# IDMA register map
Vendor: Texas Instruments
Peripheral module from a debugger description file (folder omap34xx).
Registers are 32-bit, read-write, reset values left out (the file's numbers can be read two ways) unless marked. A register's access mark holds for its fields unless they carry their own. Offsets are as the file gives them; lines under a group give offsets from that group; [hi:lo] are bit positions; {n}, {i} and the like mark numbered series; 'fields as' and 'values as' point back to an identical list; <NAME> marks a mode.

## IDMA
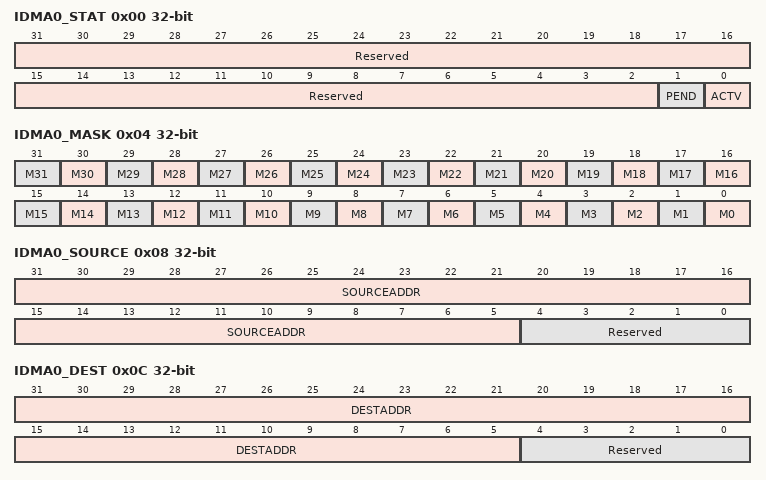
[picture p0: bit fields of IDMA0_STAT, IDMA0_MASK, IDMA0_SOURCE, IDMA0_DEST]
0x00 IDMA0_STAT ro — IDMA Channel 0 Status Register
  [31:2] Reserved — Reads return 0s
  [1] PEND — Pending transfer: Set when control registers are written to by the CPU and there is already an active transfer in progress (ACTV = 1) and cleared when the transfer becomes active.PEND = 1: Transfer is pending PEND = 0: No pending transfer
  [0] ACTV — Active transfer: Set when channel 0 begins reading data from the source address and cleared following the last write to the destination address.ACTV = 1: Active transfer ACTV = 0: No active transfer
0x04 IDMA0_MASK — IDMA Channel 0 Mask Register
  [n] M{n} (n=0..31) — Register Mask bit:M{n} = 1: Register access blocked (masked)M{n} = 0: Register access permitted (not masked)
0x08 IDMA0_SOURCE — IDMA Channel 0 Source Address Register
  [31:5] SOURCEADDR — Source Address: Must point to a 32-byte-aligned (e.g. window-aligned) memory location local to DSP megamodule or to a valid configuration register space.
  [4:0] Reserved — Write 0s for future compatibility.Read returns 0.
0x0C IDMA0_DEST — IDMA Channel 0 Destination Address Register
  [31:5] DESTADDR — Destination Address: Must point to a 32-byte-aligned (e.g. windowaligned) memory location local to DSP megamodule or to a valid configuration register space.
  [4:0] Reserved — Write 0s for future compatibility.Read returns 0.
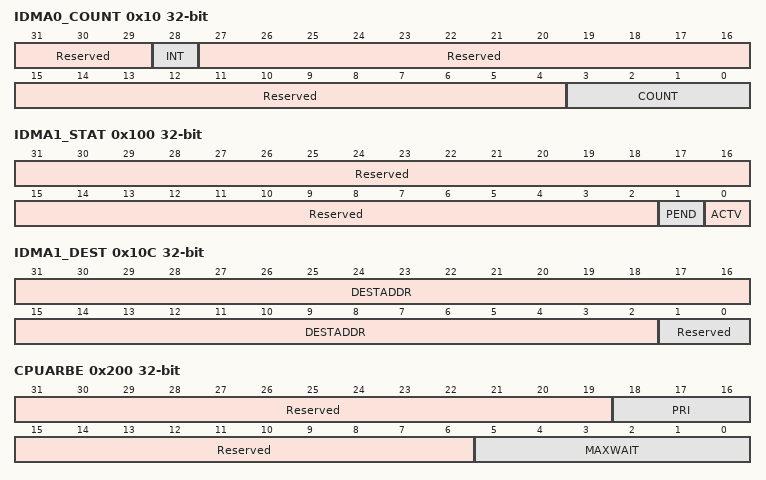
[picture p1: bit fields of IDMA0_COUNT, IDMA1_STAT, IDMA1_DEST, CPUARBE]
0x10 IDMA0_COUNT — IDMA Channel 0 Count Register
  [31:29] Reserved — Write 0s for future compatibility. Read returns 0.
  [28] INT — CPU interrupt enable INT = 1: Interrupt CPU (IDMA_INT0) on completion INT = 0: Do not interrupt CPU on completion
  [27:4] Reserved — Write 0s for future compatibility. Read returns 0.
  [3:0] COUNT — Window count COUNT = 0000: Transfer to/from one 32-word window COUNT = n: Transfer to/from n+1 32-word windows
0x100 IDMA1_STAT ro — IDMA Channel 1 Status Register
  [31:2] Reserved — Write 0s for future compatibility.Read returns 0.
  [1] PEND — Pending transfer: Set when control registers are written to by the CPU and there is already an active transfer in progress (ACTV = 1) and cleared when the transfer becomes active.PEND = 1: Transfer is pendingPEND = 0: No pending transfer
  [0] ACTV — Active transfer: Set when channel 1 begins reading data from the source address and cleared following the last write to the destination address.ACTV = 1: Active transferACTV = 0: No active transfer
0x108 IDMA1_SOURCE — IDMA Channel 1 Source Address Register
  [31:0] SOURCEADDR — Source Address: Must point to a word-aligned memory location local to GEM. When performing a block fill (IDMA1_COUNT.FILL = 1) the source address is the fill value. Note that when performing a Fill Mode transfer all 32-bits of the SOURCEADDR are writeable and when performing a linear transfer the two LSBs are implemented as 00b.
0x10C IDMA1_DEST access per field — IDMA Channel 1 Destination Address Register
  [31:2] DESTADDR rw — Destination Address: Must point to a word-aligned memory location local to DSP megamodule.
  [1:0] Reserved ro — Reads return 0sWrite 0 for further compaibility
0x200 CPUARBE — CPU Arbitration Control
  [31:19] Reserved — Write 0s for future compatibility.Read returns 0.
  [18:16] PRI — Priority
    0=Highest priority; 1=2nd highest priority; 2=3rd highest priority; {v}={v+1}th highest priority (v=3..6); 7=Lowest priority
  [15:6] Reserved — Write 0s for future compatibility.Read returns 0.
  [5:0] MAXWAIT — Maximum Wait time (in UMC/EMC cycles)
    0=Always stalls due to higher priority requestor; 1=Maximum wait of 1 cycles (1/2 = 50% access); 2=Maximum wait of 2 cycles (1/3 = 33% access); 4=Maximum wait of 4 cycles (1/5 = 20% access); 8=Maximum wait of 8 cycles (1/9 = 11% access); 16=Maximum wait of 16 cycles (1/17 = 6% access); 32=Maximum wait of 32 cycles (1/33 = 3% access)
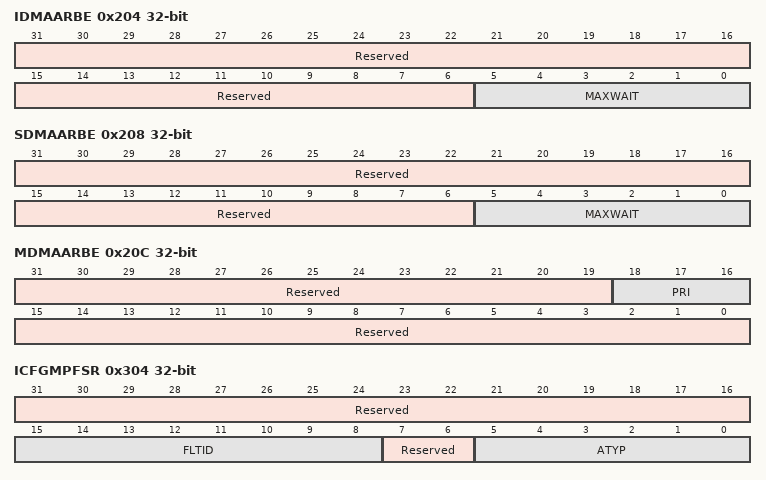
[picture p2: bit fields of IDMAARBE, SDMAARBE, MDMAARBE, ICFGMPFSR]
0x204 IDMAARBE — IDMA Arbitration control
  [31:6] Reserved — Write 0s for future compatibility.Read returns 0.
  [5:0] MAXWAIT — Maximum Wait time (in UMC/EMC cycles)
    values as CPUARBE.MAXWAIT
0x208 SDMAARBE
  fields as IDMAARBE
0x20C MDMAARBE
  [31:19] Reserved — Write 0s for future compatibility.Read returns 0.
  [18:16] PRI — Priority
    values as CPUARBE.PRI
  [15:0] Reserved — Write 0s for future compatibility.Read returns 0.
0x300 ICFGMPFAR ro — ICFG Memory Protection Fault Address Register
  [31:0] ADDR — Fault Address
0x304 ICFGMPFSR ro — ICFG Memory Protection Fault Status Register
  [31:16] Reserved — Write 0s for future compatibility.Read returns 0.
  [15:8] FLTID — Faulted ID:VBUS PrivID of faulting requestor. This field is valid only if LE is zero.
  [7:6] Reserved — Write 0s for future compatibility.Read returns 0.
  [5:0] ATYP — Access type
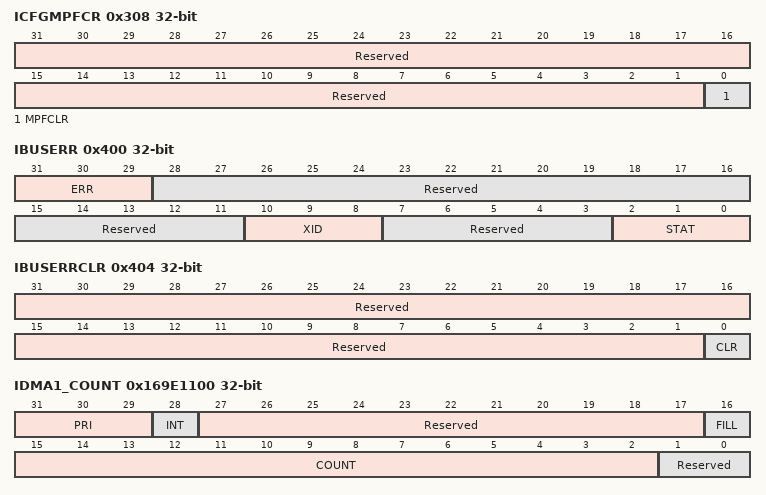
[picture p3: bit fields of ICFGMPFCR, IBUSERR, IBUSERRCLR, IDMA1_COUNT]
0x308 ICFGMPFCR wo — ICFG Memory Protection Fault Command Register
  [31:1] Reserved — Write 0s for future compatibility.Read returns 0.
  [0] MPFCLR — Write 0: No effectWrite 1: Clear fault logged information
0x400 IBUSERR ro — Bus Access Error Register
  [31:29] ERR — Error detected
    0=No error; 1=MDMA Read Status Error detected; 2=MDMA Write Status Error detected; 3=CFG Read Status Error detected; 4=CFG Write Status Error detected
  [28:11] Reserved — Write 0s for future compatibility.Read returns 0.
  [10:8] XID — Transaction IDStores the Transaction ID when an error is detected on the response. Value should match the command id for the access that resulted in an error.
  [7:3] Reserved — Write 0s for future compatibility.Read returns 0.
  [2:0] STAT — Transaction StatusStores the non-zero status/error code that wasdetected on the response to an access
    0=Success (should not cause error to be latched), or unrecognized RID/WID (should cause error to be latched); 1=Addressing error; 2=Privilege error; 3=Timeout error; 4=Data error; 7=Exclusive-operation failure
0x404 IBUSERRCLR wo — Bus Access Error Clear
  [31:1] Reserved — Write 0s for future compatibility.Read returns 0.
  [0] CLR — Clear ErrorCLR = 0: Writes of 0 have no effect.CLR = 1: Write of 1 clears all bits in the IBUSERRregister. Once an error is detected, the MDMA Error register must be cleared before additional errors canbe detected/stored.
0x169E1100 IDMA1_COUNT — IDMA Channel 0 Count Register
  [31:29] PRI — Transfer priority. Used for arbitration between CPU and DMA accesses when there are conflicts.PRI = 111b: Low priorityPRI = 000b: High priority
  [28] INT — CPU interrupt enableINT = 1: Interrupt CPU (IDMA_INT1) on completionINT = 0: Do not interrupt CPU on completion
  [27:17] Reserved — Write 0s for future compatibility.Read returns 0.
  [16] FILL — Block fill:FILL = 1: Perform a block fill using the Source address field as the fill value to the memory buffer pointed to by the Destination address field.FILL = 0: Block transfer from the source address to the destination address.
  [15:2] COUNT — 16-bit byte count. Must be a multiple of 4 bytes. A transfer count of zero will not transfer any data, but will generate an interrupt if requested in the INT field.
  [1:0] Reserved — Write 0s for future compatibility.Read returns 0.
